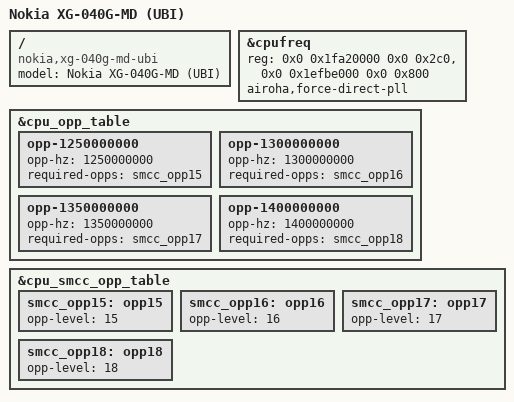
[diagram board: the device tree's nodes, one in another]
// SPDX-License-Identifier: GPL-2.0-only OR MIT

#include "an7581-nokia_xg-040g-md-common.dtsi"
#include "an758x-nokia_xg-040g-ubi-parts.dtsi"

/ {
	model = "Nokia XG-040G-MD (UBI)";
	compatible = "nokia,xg-040g-md-ubi", "airoha,an7581",
		     "airoha,en7581";
};

/* Keep the SoC/ATF state numbering; only this board opts into higher OPPs. */
&cpufreq {
	reg = <0x0 0x1fa20000 0x0 0x2c0>,
	      <0x0 0x1efbe000 0x0 0x800>;
	reg-names = "chip-scu", "mcucfg";
	airoha,force-direct-pll;
};

&cpu_opp_table {
	opp-1250000000 {
		opp-hz = /bits/ 64 <1250000000>;
		required-opps = <&smcc_opp15>;
	};

	opp-1300000000 {
		opp-hz = /bits/ 64 <1300000000>;
		required-opps = <&smcc_opp16>;
	};

	opp-1350000000 {
		opp-hz = /bits/ 64 <1350000000>;
		required-opps = <&smcc_opp17>;
	};

	opp-1400000000 {
		opp-hz = /bits/ 64 <1400000000>;
		required-opps = <&smcc_opp18>;
	};
};

&cpu_smcc_opp_table {
	smcc_opp15: opp15 {
		opp-level = <15>;
	};

	smcc_opp16: opp16 {
		opp-level = <16>;
	};

	smcc_opp17: opp17 {
		opp-level = <17>;
	};

	smcc_opp18: opp18 {
		opp-level = <18>;
	};
};
